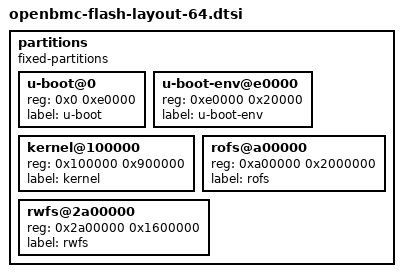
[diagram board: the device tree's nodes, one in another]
partitions {
	compatible = "fixed-partitions";
	#address-cells = <1>;
	#size-cells = <1>;
	u-boot@0 {
		reg = <0x0 0xe0000>;  
		label = "u-boot";
	};
	u-boot-env@e0000 {
		reg = <0xe0000 0x20000>;  
		label = "u-boot-env";
	};
	kernel@100000 {
		reg = <0x100000 0x900000>;  
		label = "kernel";
	};
	rofs@a00000 {
		reg = <0xa00000 0x2000000>;  
		label = "rofs";
	};
	rwfs@2a00000 {
		reg = <0x2a00000 0x1600000>;  
		label = "rwfs";
	};
};
